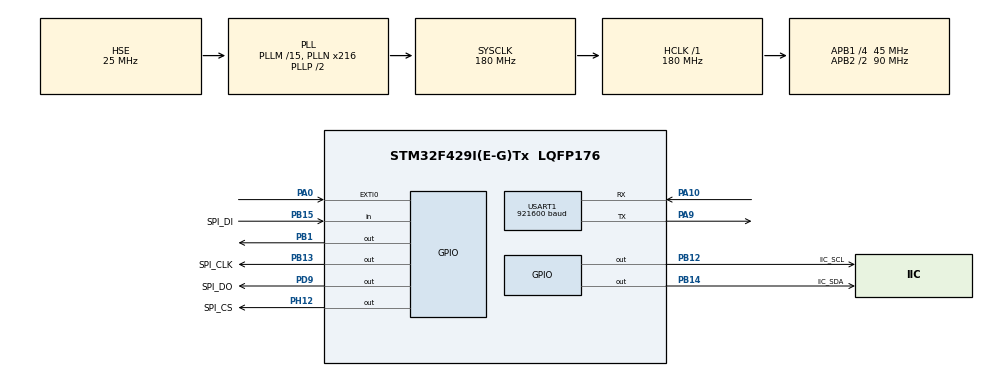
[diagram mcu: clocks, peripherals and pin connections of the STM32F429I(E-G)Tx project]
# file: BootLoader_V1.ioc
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Mcu.Family=STM32F4
Mcu.Name=STM32F429I(E-G)Tx
Mcu.Package=LQFP176
NVIC.EXTI0_IRQn=true\:0\:0\:true\:false\:true\:true\:true\:true
NVIC.PriorityGroup=NVIC_PRIORITYGROUP_4
NVIC.USART1_IRQn=true\:0\:0\:true\:false\:true\:true\:true\:true
PA0/WKUP.GPIO_ModeDefaultEXTI=GPIO_MODE_IT_RISING
PA0/WKUP.GPIO_PuPd=GPIO_PULLDOWN
PA0/WKUP.Signal=GPXTI0
PA10.Mode=Asynchronous
PA10.Signal=USART1_RX
PA13.Mode=Serial_Wire
PA13.Signal=SYS_JTMS-SWDIO
PA14.Mode=Serial_Wire
PA14.Signal=SYS_JTCK-SWCLK
PA9.Mode=Asynchronous
PA9.Signal=USART1_TX
PB1.GPIO_PuPd=GPIO_PULLUP
PB1.GPIO_Speed=GPIO_SPEED_FREQ_HIGH
PB1.PinState=GPIO_PIN_SET
PB1.Signal=GPIO_Output
PB12.GPIO_Label=IIC_SCL
PB12.GPIO_ModeDefaultOutputPP=GPIO_MODE_OUTPUT_OD
PB12.GPIO_PuPd=GPIO_PULLUP
PB12.GPIO_Speed=GPIO_SPEED_FREQ_HIGH
PB12.PinState=GPIO_PIN_SET
PB12.Signal=GPIO_Output
PB13.GPIO_Label=SPI_CLK
PB13.GPIO_Speed=GPIO_SPEED_FREQ_HIGH
PB13.Signal=GPIO_Output
PB14.GPIO_Label=IIC_SDA
PB14.GPIO_ModeDefaultOutputPP=GPIO_MODE_OUTPUT_OD
PB14.GPIO_PuPd=GPIO_PULLUP
PB14.GPIO_Speed=GPIO_SPEED_FREQ_HIGH
PB14.PinState=GPIO_PIN_SET
PB14.Signal=GPIO_Output
PB15.GPIO_Label=SPI_DI
PB15.Signal=GPIO_Input
PC14/OSC32_IN.Mode=LSE-External-Oscillator
PC14/OSC32_IN.Signal=RCC_OSC32_IN
PC15/OSC32_OUT.Mode=LSE-External-Oscillator
PC15/OSC32_OUT.Signal=RCC_OSC32_OUT
PD9.GPIO_Label=SPI_DO
PD9.GPIO_Speed=GPIO_SPEED_FREQ_HIGH
PD9.Signal=GPIO_Output
PH0/OSC_IN.Mode=HSE-External-Oscillator
PH0/OSC_IN.Signal=RCC_OSC_IN
PH1/OSC_OUT.Mode=HSE-External-Oscillator
PH1/OSC_OUT.Signal=RCC_OSC_OUT
PH12.GPIO_Label=SPI_CS
PH12.GPIO_Speed=GPIO_SPEED_FREQ_HIGH
PH12.Signal=GPIO_Output
ProjectManager.HeapSize=0x200
ProjectManager.StackSize=0x400
ProjectManager.TargetToolchain=MDK-ARM V5.32
RCC.48MHZClocksFreq_Value=90000000
RCC.AHBFreq_Value=180000000
RCC.APB1CLKDivider=RCC_HCLK_DIV4
RCC.APB1Freq_Value=45000000
RCC.APB1TimFreq_Value=90000000
RCC.APB2CLKDivider=RCC_HCLK_DIV2
RCC.APB2Freq_Value=90000000
RCC.APB2TimFreq_Value=180000000
RCC.CortexFreq_Value=180000000
RCC.HCLKFreq_Value=180000000
RCC.HSE_VALUE=25000000
RCC.HSI_VALUE=16000000
RCC.PLLM=15
RCC.PLLN=216
RCC.PLLSourceVirtual=RCC_PLLSOURCE_HSE
RCC.SYSCLKFreq_VALUE=180000000
RCC.SYSCLKSource=RCC_SYSCLKSOURCE_PLLCLK
RCC.VCOOutputFreq_Value=360000000
USART1.BaudRate=921600
USART1.VirtualMode=VM_ASYNC
board=custom

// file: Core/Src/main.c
/* USER CODE BEGIN Header */
/**
  ******************************************************************************
  * @file           : main.c
  * @brief          : Main program body
  ******************************************************************************
  * @attention
  *
  * Copyright (c) 2026 STMicroelectronics.
  * All rights reserved.
  *
  * This software is licensed under terms that can be found in the LICENSE file
  * in the root directory of this software component.
  * If no LICENSE file comes with this software, it is provided AS-IS.
  *
  ******************************************************************************
  */
/* USER CODE END Header */
#include "main.h"
#include "usart.h"
#include "gpio.h"

/* USER CODE BEGIN Includes */
#include "string.h"
#include "BootLoader.h"
#include "App_BootLoader.h"
#include "at24c64.h"
#include "w25q32.h"
/* USER CODE END Includes */

void SystemClock_Config(void);

int main(void)
{

  /* MCU Configuration--------------------------------------------------------*/

  /* Reset of all peripherals, Initializes the Flash interface and the Systick. */
  HAL_Init();

  /* Configure the system clock */
  SystemClock_Config();

  /* Initialize all configured peripherals */
  MX_GPIO_Init();
  MX_USART1_UART_Init();
  /* USER CODE BEGIN 2 */
  IIC_Init();
  SPI_Init();
  // HAL_UARTEx_ReceiveToIdle_IT(&huart1, bootLoaderReceiverBuff, BOOTLOADER_UART_RECEIVE_BUFF_SIZE);
  /* USER CODE END 2 */

  /* Infinite loop */
  while (1)
  {

    /* USER CODE BEGIN 3 */
    // App_BootLoader_Work();
  }
  /* USER CODE END 3 */
}

void SystemClock_Config(void)
{
  RCC_OscInitTypeDef RCC_OscInitStruct = {0};
  RCC_ClkInitTypeDef RCC_ClkInitStruct = {0};

  /** Configure the main internal regulator output voltage
  */
  __HAL_RCC_PWR_CLK_ENABLE();
  __HAL_PWR_VOLTAGESCALING_CONFIG(PWR_REGULATOR_VOLTAGE_SCALE1);

  /** Initializes the RCC Oscillators according to the specified parameters
  * in the RCC_OscInitTypeDef structure.
  */
  RCC_OscInitStruct.OscillatorType = RCC_OSCILLATORTYPE_HSE;
  RCC_OscInitStruct.HSEState = RCC_HSE_ON;
  RCC_OscInitStruct.PLL.PLLState = RCC_PLL_ON;
  RCC_OscInitStruct.PLL.PLLSource = RCC_PLLSOURCE_HSE;
  RCC_OscInitStruct.PLL.PLLM = 15;
  RCC_OscInitStruct.PLL.PLLN = 216;
  RCC_OscInitStruct.PLL.PLLP = RCC_PLLP_DIV2;
  RCC_OscInitStruct.PLL.PLLQ = 4;
  if (HAL_RCC_OscConfig(&RCC_OscInitStruct) != HAL_OK)
  {
    Error_Handler();
  }

  /** Activate the Over-Drive mode
  */
  if (HAL_PWREx_EnableOverDrive() != HAL_OK)
  {
    Error_Handler();
  }

  /** Initializes the CPU, AHB and APB buses clocks
  */
  RCC_ClkInitStruct.ClockType = RCC_CLOCKTYPE_HCLK|RCC_CLOCKTYPE_SYSCLK
                              |RCC_CLOCKTYPE_PCLK1|RCC_CLOCKTYPE_PCLK2;
  RCC_ClkInitStruct.SYSCLKSource = RCC_SYSCLKSOURCE_PLLCLK;
  RCC_ClkInitStruct.AHBCLKDivider = RCC_SYSCLK_DIV1;
  RCC_ClkInitStruct.APB1CLKDivider = RCC_HCLK_DIV4;
  RCC_ClkInitStruct.APB2CLKDivider = RCC_HCLK_DIV2;

  if (HAL_RCC_ClockConfig(&RCC_ClkInitStruct, FLASH_LATENCY_5) != HAL_OK)
  {
    Error_Handler();
  }
}

void Error_Handler(void)
{
  __disable_irq();
  while (1)
  {
  }
}
